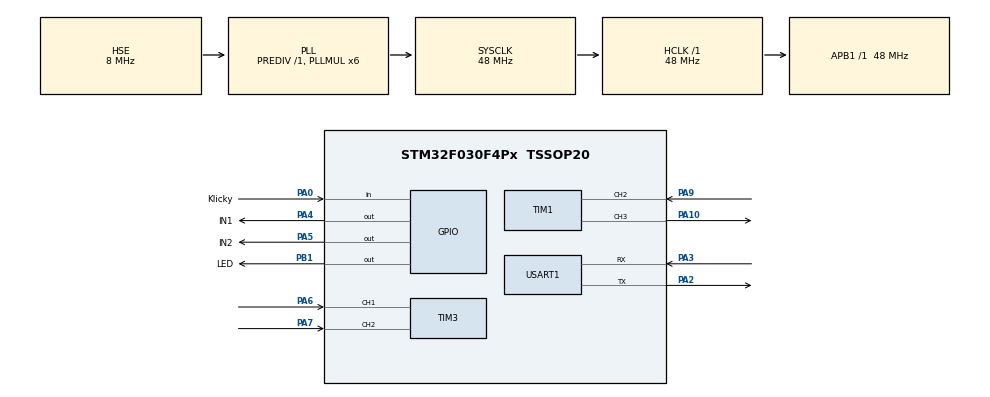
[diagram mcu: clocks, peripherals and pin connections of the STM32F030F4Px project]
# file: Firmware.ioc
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Mcu.Family=STM32F0
Mcu.Name=STM32F030F4Px
Mcu.Package=TSSOP20
NVIC.TIM17_IRQn=true\:0\:0\:false\:false\:true\:true\:true\:true
PA0.GPIO_Label=Klicky
PA0.Signal=GPIO_Input
PA10.Signal=S_TIM1_CH3
PA13.Mode=Serial_Wire
PA13.Signal=SYS_SWDIO
PA14.Mode=Serial_Wire
PA14.Signal=SYS_SWCLK
PA2.Mode=Asynchronous
PA2.Signal=USART1_TX
PA3.Mode=Asynchronous
PA3.Signal=USART1_RX
PA4.GPIO_Label=IN1
PA4.Signal=GPIO_Output
PA5.GPIO_Label=IN2
PA5.Signal=GPIO_Output
PA6.Signal=S_TIM3_CH1
PA7.Signal=S_TIM3_CH2
PA9.Signal=S_TIM1_CH2
PB1.GPIO_Label=LED
PB1.PinState=GPIO_PIN_SET
PB1.Signal=GPIO_Output
PF0-OSC_IN.Mode=HSE-External-Oscillator
PF0-OSC_IN.Signal=RCC_OSC_IN
PF1-OSC_OUT.Mode=HSE-External-Oscillator
PF1-OSC_OUT.Signal=RCC_OSC_OUT
ProjectManager.HeapSize=0x200
ProjectManager.StackSize=0x400
ProjectManager.TargetToolchain=STM32CubeIDE
RCC.AHBFreq_Value=48000000
RCC.APB1Freq_Value=48000000
RCC.APB1TimFreq_Value=48000000
RCC.HCLKFreq_Value=48000000
RCC.PLLMUL=RCC_PLL_MUL6
RCC.PLLSourceVirtual=RCC_PLLSOURCE_HSE
RCC.SYSCLKFreq_VALUE=48000000
RCC.SYSCLKSource=RCC_SYSCLKSOURCE_PLLCLK
SH.S_TIM1_CH2.0=TIM1_CH2,PWM_Input_2
SH.S_TIM1_CH3.0=TIM1_CH3,PWM Generation3 CH3
SH.S_TIM3_CH1.0=TIM3_CH1,Encoder_Interface
SH.S_TIM3_CH2.0=TIM3_CH2,Encoder_Interface
TIM1.Channel-PWM\ Generation3\ CH3=TIM_CHANNEL_3
TIM17.Period=50000-1
TIM17.Prescaler=48-1
USART1.VirtualMode-Asynchronous=VM_ASYNC
VP_TIM17_VS_ClockSourceINT.Mode=Enable_Timer
board=custom

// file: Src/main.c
/* USER CODE BEGIN Header */

/**

  ******************************************************************************

  * @file           : main.c

  * @brief          : Main program body

  ******************************************************************************

  * @attention

  *

  * Copyright (c) 2024 STMicroelectronics.

  * All rights reserved.

  *

  * This software is licensed under terms that can be found in the LICENSE file

  * in the root directory of this software component.

  * If no LICENSE file comes with this software, it is provided AS-IS.

  *

  ******************************************************************************

  */

/* USER CODE END Header */
#include "main.h"
#include "tim.h"
#include "usart.h"
#include "gpio.h"

/* USER CODE BEGIN Includes */

#include "Capture.h"

#include "Retarget.h"

#include "Encoder.h"

#include "Motor.h"

#include "PID.h"

/* USER CODE END Includes */

/* USER CODE BEGIN PV */

uint8_t tx_buffer[] = "Hello World";

/* USER CODE END PV */

void SystemClock_Config(void);

int main(void)
{

  /* MCU Configuration--------------------------------------------------------*/

  /* Reset of all peripherals, Initializes the Flash interface and the Systick. */
  HAL_Init();

  /* Configure the system clock */
  SystemClock_Config();

  /* Initialize all configured peripherals */
  MX_GPIO_Init();
  MX_TIM1_Init();
  MX_TIM3_Init();
  MX_USART1_UART_Init();
  MX_TIM17_Init();
  /* USER CODE BEGIN 2 */
//    RetargetInit(&huart1);
//  captureInit();

//  encoderInit();

//    captureInit();

    motorInit();

    encoderInit();

    pidParamInit();
    setMotorDirection(0);

    setMotorSpeed(1000);

  /* USER CODE END 2 */

  /* Infinite loop */
  /* USER CODE BEGIN WHILE */

  while (1)

  {

//      setMotorSpeed(1000);

//      calcuateSpeed();

    /* USER CODE END WHILE */

  }
}

void SystemClock_Config(void)
{
  RCC_OscInitTypeDef RCC_OscInitStruct = {0};
  RCC_ClkInitTypeDef RCC_ClkInitStruct = {0};
  RCC_PeriphCLKInitTypeDef PeriphClkInit = {0};

  /** Initializes the RCC Oscillators according to the specified parameters
  * in the RCC_OscInitTypeDef structure.
  */
  RCC_OscInitStruct.OscillatorType = RCC_OSCILLATORTYPE_HSE;
  RCC_OscInitStruct.HSEState = RCC_HSE_ON;
  RCC_OscInitStruct.PLL.PLLState = RCC_PLL_ON;
  RCC_OscInitStruct.PLL.PLLSource = RCC_PLLSOURCE_HSE;
  RCC_OscInitStruct.PLL.PLLMUL = RCC_PLL_MUL6;
  RCC_OscInitStruct.PLL.PREDIV = RCC_PREDIV_DIV1;
  if (HAL_RCC_OscConfig(&RCC_OscInitStruct) != HAL_OK)
  {
    Error_Handler();
  }

  /** Initializes the CPU, AHB and APB buses clocks
  */
  RCC_ClkInitStruct.ClockType = RCC_CLOCKTYPE_HCLK|RCC_CLOCKTYPE_SYSCLK
                              |RCC_CLOCKTYPE_PCLK1;
  RCC_ClkInitStruct.SYSCLKSource = RCC_SYSCLKSOURCE_PLLCLK;
  RCC_ClkInitStruct.AHBCLKDivider = RCC_SYSCLK_DIV1;
  RCC_ClkInitStruct.APB1CLKDivider = RCC_HCLK_DIV1;

  if (HAL_RCC_ClockConfig(&RCC_ClkInitStruct, FLASH_LATENCY_1) != HAL_OK)
  {
    Error_Handler();
  }
  PeriphClkInit.PeriphClockSelection = RCC_PERIPHCLK_USART1;
  PeriphClkInit.Usart1ClockSelection = RCC_USART1CLKSOURCE_PCLK1;
  if (HAL_RCCEx_PeriphCLKConfig(&PeriphClkInit) != HAL_OK)
  {
    Error_Handler();
  }
}

void Error_Handler(void)
{
  __disable_irq();
  while (1)
  {
  }
}
